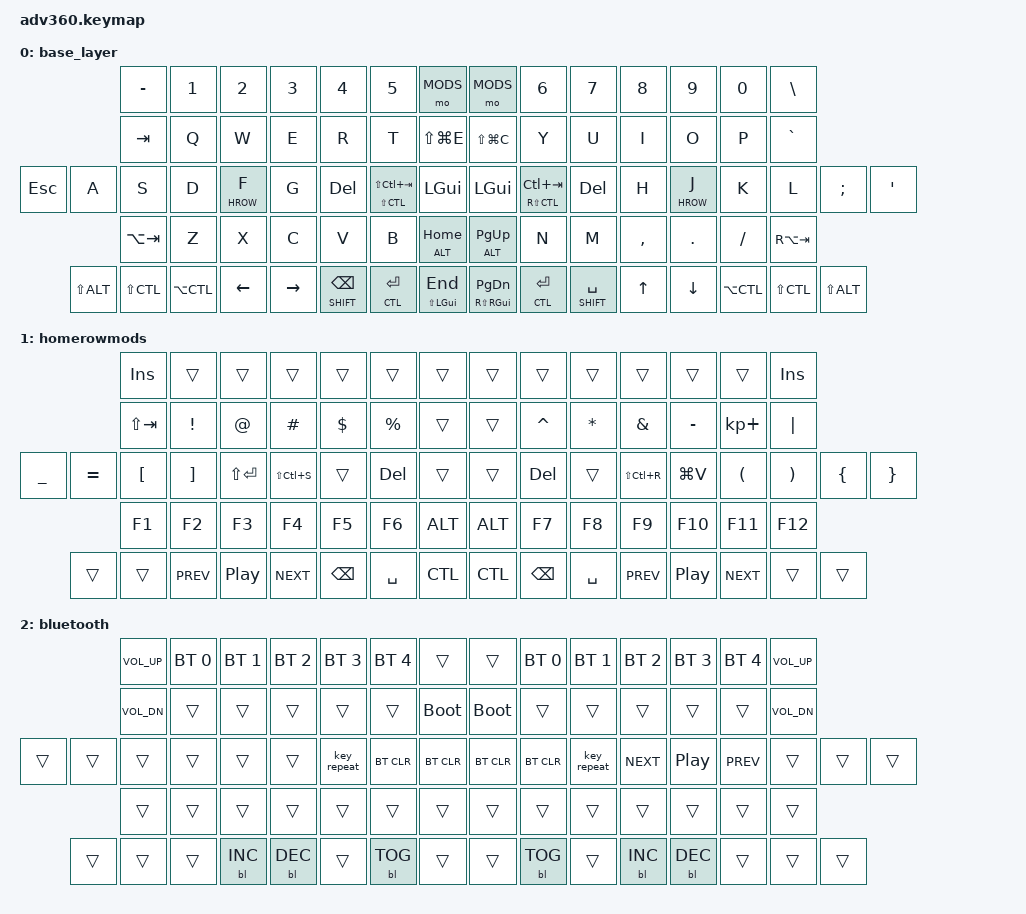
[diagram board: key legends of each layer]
#include <behaviors.dtsi>
#include <dt-bindings/zmk/keys.h>
#include <dt-bindings/zmk/bt.h>
#include <dt-bindings/zmk/rgb.h>
#include <dt-bindings/zmk/backlight.h>

#define _ &trans
#define CTL LCTRL
#define ALT LALT
#define SHIFT LSHFT

#define BASE 0
#define HROW 1
#define MODS 2

&mt {
    tapping-term-ms = <200>;
    quick-tap-ms = <200>;
//    global-quick-tap;
};

/ {
    behaviors {
        rt: retro_momentary_tap {
            compatible = "zmk,behavior-hold-tap";
            #binding-cells = <2>;
            label = "rt";
            bindings = <&kp>, <&kp>;
            tapping-term-ms = <100>;
            retro-tap;
        };
    };

    keymap {
        compatible = "zmk,keymap";

        base_layer {
            bindings = <
// ╔══════════════════════════════╦══════════════════════════════╦══════════════════════════════╦══════════════════════════════╦══════════════════════════════╦══════════════════════════════╦══════════════════════════════╦══════════════════════════════╦══════════════════════════════╦══════════════════════════════╦══════════════════════════════╦══════════════════════════════╦══════════════════════════════╦══════════════════════════════╗
// ║              0               ║              1               ║              2               ║              3               ║              4               ║              5               ║              6               ║              7               ║              8               ║              9               ║              10              ║              11              ║              12              ║              13              ║
              &kp MINUS                        &kp N1                         &kp N2                          &kp N3                        &kp N4                         &kp N5                        &mo MODS                       &mo MODS                       &kp N6                          &kp N7                         &kp N8                         &kp N9                          &kp N0                       &kp BSLH
// ╠══════════════════════════════╬══════════════════════════════╬══════════════════════════════╬══════════════════════════════╬══════════════════════════════╬══════════════════════════════╬══════════════════════════════╬══════════════════════════════╬══════════════════════════════╬══════════════════════════════╬══════════════════════════════╬══════════════════════════════╬══════════════════════════════╬══════════════════════════════╣
// ║              14              ║              15              ║              16              ║              17              ║              18              ║              19              ║              20              ║              21              ║              22              ║              23              ║              24              ║              25              ║              26              ║              27              ║
               &kp TAB                         &kp Q                          &kp W                          &kp E                          &kp R                          &kp T                         &kp LS(LG(E))                 &kp LS(LG(C))                     &kp Y                         &kp U                           &kp I                          &kp O                          &kp P                        &kp GRAVE
// ╠══════════════════════════════╬══════════════════════════════╬══════════════════════════════╬══════════════════════════════╬══════════════════════════════╬══════════════════════════════╬══════════════════════════════╬══════════════════════════════╬══════════════════════════════╬══════════════════════════════╬══════════════════════════════╬══════════════════════════════╬══════════════════════════════╬══════════════════════════════╣══════════════════════════════╬══════════════════════════════╬══════════════════════════════╬══════════════════════════════╣
// ║              28              ║              29              ║              30              ║              31              ║              32              ║              33              ║              34              ║              64              ║              65              ║              66              ║              67              ║              35              ║              36              ║              37              ║              38              ║              39              ║              40              ║              41              ║
                &kp ESC                        &kp A                           &kp S                         &kp D                         &lt HROW F                       &kp G                        &kp DELETE              &mt LS(CTL) LS(LC(TAB))              &kp LGUI                        &kp LGUI                 &rt RS(CTL) LC(TAB) 	           &kp DELETE                        &kp H                       &lt HROW J                        &kp K                          &kp L                         &kp SEMI                      &kp SQT
// ╠══════════════════════════════╬══════════════════════════════╬══════════════════════════════╬══════════════════════════════╬══════════════════════════════╬══════════════════════════════╬═════════════════════════════════════════════════════════════╬══════════════════════════════╬══════════════════════════════╬══════════════════════════════╬══════════════════════════════╬══════════════════════════════╬══════════════════════════════╣
// ║              42              ║              43              ║              44              ║              45              ║              46              ║              47              ║              70              ║              71              ║              48              ║              49              ║              50              ║              51              ║              52              ║              53              ║
               &kp LA(TAB)                     &kp Z                           &kp X                          &kp C                          &kp V                          &kp B             			&rt ALT HOME                   &rt ALT PG_UP                     &kp N                          &kp M                        &kp COMMA                       &kp DOT                        &kp FSLH                      &kp RA(TAB)
// ╠══════════════════════════════╬══════════════════════════════╬══════════════════════════════╬══════════════════════════════╬══════════════════════════════╬══════════════════════════════╬══════════════════════════════╬══════════════════════════════╬══════════════════════════════╬══════════════════════════════╬══════════════════════════════╬══════════════════════════════╬══════════════════════════════╬══════════════════════════════╣
// ║              54              ║              55              ║              56              ║              57              ║              58              ║              64              ║              65              ║              66              ║              67              ║              59              ║              60              ║              61              ║              62              ║              63              ║
               &kp LS(ALT)                   &kp LS(CTL)                  &kp LA(CTL)                   &kp LEFT                      &kp RIGHT                     &rt SHIFT BSPC                 &mt CTL ENTER               &rt LS(LGUI) END                &rt RS(RGUI) PG_DN               &mt CTL ENTER                 &rt SHIFT SPACE                    &kp UP                        &kp DOWN                           &kp LA(CTL)                            &kp LS(CTL)                     &kp LS(ALT)
// ╚══════════════════════════════╩══════════════════════════════╩══════════════════════════════╩══════════════════════════════╩══════════════════════════════╩══════════════════════════════╩══════════════════════════════╩══════════════════════════════╩══════════════════════════════╩══════════════════════════════╩══════════════════════════════╩══════════════════════════════╩══════════════════════════════╩══════════════════════════════╝
            >;
        };


        homerowmods {
            bindings = <
// ╔══════════════════════════════╦══════════════════════════════╦══════════════════════════════╦══════════════════════════════╦══════════════════════════════╦══════════════════════════════╦══════════════════════════════╦══════════════════════════════╦══════════════════════════════╦══════════════════════════════╦══════════════════════════════╦══════════════════════════════╦══════════════════════════════╦══════════════════════════════╗
// ║              0               ║              1               ║              2               ║              3               ║              4               ║              5               ║              6               ║              7               ║              8               ║              9               ║              10              ║              11              ║              12              ║              13              ║
             &kp INSERT                          _                              _                              _                              _                              _                              _                              _                              _                              _                               _                              _                              _                         &kp INSERT
// ╠══════════════════════════════╬══════════════════════════════╬══════════════════════════════╬══════════════════════════════╬══════════════════════════════╬══════════════════════════════╬══════════════════════════════╬══════════════════════════════╬══════════════════════════════╬══════════════════════════════╬══════════════════════════════╬══════════════════════════════╬══════════════════════════════╬══════════════════════════════╣
// ║              14              ║              15              ║              16              ║              17              ║              18              ║              19              ║              20              ║              21              ║              22              ║              23              ║              24              ║              25              ║              26              ║              27              ║
              &kp LS(TAB)                     &kp EXCL                        &kp AT                        &kp HASH                       &kp DLLR                     &kp PERCENT                          _                              _                          &kp CARET                      &kp STAR                       &kp AMPS                      &kp MINUS                      &kp KP_PLUS                    &kp PIPE
// ╠══════════════════════════════╬══════════════════════════════╬══════════════════════════════╬══════════════════════════════╬══════════════════════════════╬══════════════════════════════╬══════════════════════════════╬══════════════════════════════╬══════════════════════════════╬══════════════════════════════╬══════════════════════════════╬══════════════════════════════╬══════════════════════════════╬══════════════════════════════╣
// ║              28              ║              29              ║              30              ║              31              ║              32              ║              33              ║              64              ║              65              ║              66              ║              67              ║              34              ║              35              ║              36              ║              37              ║              38              ║              39              ║              40              ║              41              ║
               &kp UNDER                      &kp EQUAL                      &kp LBKT                       &kp RBKT                     &kp LS(ENTER)                 &kp LS(LC(S))                        _                          &kp DELETE                          _                              _                         &kp DELETE                          _                        &kp LS(LC(R))                   &kp LG(V)                     &kp LPAR                       &kp RPAR                       &kp LBRC                       &kp RBRC
// ╠══════════════════════════════╬══════════════════════════════╬══════════════════════════════╬══════════════════════════════╬══════════════════════════════╬══════════════════════════════╬═════════════════════════════════════════════════════════════╬══════════════════════════════╬══════════════════════════════╬══════════════════════════════╬══════════════════════════════╬══════════════════════════════╬══════════════════════════════╣
// ║              42              ║              43              ║              44              ║              45              ║              46              ║              47              ║              70              ║              71              ║              48              ║              49              ║              50              ║              51              ║              52              ║              53              ║
                &kp F1                         &kp F2                         &kp F3                         &kp F4                         &kp F5                         &kp F6                       &kp ALT                        &kp ALT                        &kp F7                         &kp F8                          &kp F9                        &kp F10                        &kp F11                        &kp F12
// ╠══════════════════════════════╬══════════════════════════════╬══════════════════════════════╬══════════════════════════════╬══════════════════════════════╬══════════════════════════════╝╚═════════════════════════════╬══════════════════════════════╬══════════════════════════════╬══════════════════════════════╬══════════════════════════════╬══════════════════════════════╣
// ║              54              ║              55              ║              56              ║              57              ║              58              ║░║              59            ║              60              ║              61              ║              62              ║              63              ║
                   _                              _                         &kp C_PREV                 &kp C_PLAY_PAUSE                    &kp C_NEXT          				&kp BSPC                     &kp SPACE                     &kp CTL                       &kp CTL                      &kp BSPC                       &kp SPACE   					&kp C_PREV                  &kp C_PLAY_PAUSE                  &kp C_NEXT                          _                              _
// ╚══════════════════════════════╩══════════════════════════════╩══════════════════════════════╩══════════════════════════════╩══════════════════════════════╩══════════════════════════════╩══════════════════════════════╩══════════════════════════════╩══════════════════════════════╩══════════════════════════════╩══════════════════════════════╩══════════════════════════════╩══════════════════════════════╩══════════════════════════════╝
            >;
        };

        bluetooth {
            bindings = <
// ╔══════════════════════════════╦══════════════════════════════╦══════════════════════════════╦══════════════════════════════╦══════════════════════════════╦══════════════════════════════╦══════════════════════════════╦══════════════════════════════╦══════════════════════════════╦══════════════════════════════╦══════════════════════════════╦══════════════════════════════╦══════════════════════════════╦══════════════════════════════╗
// ║              0               ║              1               ║              2               ║              3               ║              4               ║              5               ║              6               ║              7               ║              8               ║              9               ║              10              ║              11              ║              12              ║              13              ║
             &kp C_VOL_UP                  &bt BT_SEL 0                    &bt BT_SEL 1                   &bt BT_SEL 2                   &bt BT_SEL 3                   &bt BT_SEL 4                        _                              _                        &bt BT_SEL 0                   &bt BT_SEL 1                    &bt BT_SEL 2                   &bt BT_SEL 3                   &bt BT_SEL 4                   &kp C_VOL_UP
// ╠══════════════════════════════╬══════════════════════════════╬══════════════════════════════╬══════════════════════════════╬══════════════════════════════╬══════════════════════════════╬══════════════════════════════╬══════════════════════════════╬══════════════════════════════╬══════════════════════════════╬══════════════════════════════╬══════════════════════════════╬══════════════════════════════╬══════════════════════════════╣
// ║              14              ║              15              ║              16              ║              17              ║              18              ║              19              ║              20              ║              21              ║              22              ║              23              ║              24              ║              25              ║              26              ║              27              ║
             &kp C_VOL_DN                         _                              _                              _                              _                              _                         &bootloader                    &bootloader                         _                              _                              _                              _                              _                        &kp C_VOL_DN
// ╠══════════════════════════════╬══════════════════════════════╬══════════════════════════════╬══════════════════════════════╬══════════════════════════════╬══════════════════════════════╬══════════════════════════════╬══════════════════════════════╬══════════════════════════════╬══════════════════════════════╬══════════════════════════════╬══════════════════════════════╬══════════════════════════════╬══════════════════════════════╣
// ║              28              ║              29              ║              30              ║              31              ║              32              ║              33              ║              34              ║              35              ║              36              ║              37              ║              38              ║              39              ║              40              ║              41              ║
                   _                              _                              _                              _                              _                              _                         &key_repeat           			&bt BT_CLR                     &bt BT_CLR                     &bt BT_CLR                     &bt BT_CLR                 &key_repeat                     &kp C_NEXT                  &kp C_PLAY_PAUSE                  &kp C_PREV                          _                              _                              _
// ╠══════════════════════════════╬══════════════════════════════╬══════════════════════════════╬══════════════════════════════╬══════════════════════════════╬══════════════════════════════╬═════════════════════════════════════════════════════════════╬══════════════════════════════╬══════════════════════════════╬══════════════════════════════╬══════════════════════════════╬══════════════════════════════╬══════════════════════════════╣
// ║              42              ║              43              ║              44              ║              45              ║              46              ║              47              ║░░░░░░░░░░░░░░░░░░░░░░░░░░░░░░░░░░░░░░░░░░░░░░░░░░░░░░░░░░░░░║              48              ║              49              ║              50              ║              51              ║              52              ║              53              ║
                   _                              _                              _                              _                              _                              _                              _                              _                              _                              _                              _                              _                              _                              _
// ╠══════════════════════════════╬══════════════════════════════╬══════════════════════════════╬══════════════════════════════╬══════════════════════════════╬══════════════════════════════╝╚══════════════════════════════╬══════════════════════════════╬══════════════════════════════╬══════════════════════════════╬══════════════════════════════╬══════════════════════════════╣
// ║              54              ║              55              ║              56              ║              57              ║              58              ║░░░░░░░░░░░░░░░░░░░░░░░░░░░░░░░░░░░░░░░░░░░░░░░░░░░░░░░░░░░░░░░░░░░░░░░░░░░░░░░░░░░░░░░░░░░░░░░░░░░░░░░░░░░░░░░░░░░░░░░░░░░║              59              ║              60              ║              61              ║              62              ║              63              ║
                   _                              _                              _                         &bl BL_INC                     &bl BL_DEC                          _                         &bl BL_TOG                          _                              _                         &bl BL_TOG                          _&bl BL_INC                     &bl BL_DEC                          _                              _                              _
// ╚══════════════════════════════╩══════════════════════════════╩══════════════════════════════╩══════════════════════════════╩══════════════════════════════╩══════════════════════════════╩══════════════════════════════╩══════════════════════════════╩══════════════════════════════╩══════════════════════════════╩══════════════════════════════╩══════════════════════════════╩══════════════════════════════╩══════════════════════════════╝
            >;
        };

    };
};
